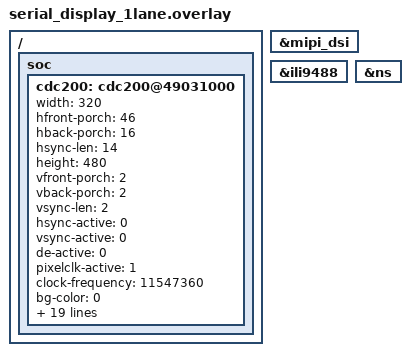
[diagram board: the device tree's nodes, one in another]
/* Copyright (C) 2024 Alif Semiconductor - All Rights Reserved.
 * Use, distribution and modification of this code is permitted under the
 * terms stated in the Alif Semiconductor Software License Agreement
 *
 * You should have received a copy of the Alif Semiconductor Software
 * License Agreement with this file. If not, please write to:
 * contact@alifsemi.com, or visit: https://alifsemi.com/license
 *
 */

/ {
	soc {
		cdc200: cdc200@49031000 {
			width = <320>;
			hfront-porch = <46>;
			hback-porch = <16>;
			hsync-len = <14>;

			height = <480>;
			vfront-porch = <2>;
			vback-porch = <2>;
			vsync-len = <2>;

			hsync-active = <0>;
			vsync-active = <0>;
			de-active = <0>;
			pixelclk-active = <1>;

			clock-frequency = <11547360>;

			bg-color = <0>;
			enable-l1 = <1>;
			pixel-fmt-l1 = "rgb-565";
			def-back-color-l1 = <0>;
			win-x0-l1 = <0>;
			win-y0-l1 = <0>;
			win-x1-l1 = <320>;
			win-y1-l1 = <480>;
			blend-factor1-l1 = <4>;
			blend-factor2-l1 = <5>;
			const-alpha-l1 = <0xff>;
			enable-l2 = <0>;
			pixel-fmt-l2 = "undefined";
			win-x0-l2 = <0>;
			win-y0-l2 = <0>;
			win-x1-l2 = <0>;
			win-y1-l2 = <0>;
			blend-factor1-l2 = <6>;
			blend-factor2-l2 = <7>;
			const-alpha-l2 = <0xff>;
		};
	};
};

&mipi_dsi {
	//dpi-video-pattern-gen = "vertical-color-bar";
	//dpi-video-pattern-gen = "horizontal-color-bar";
	//dpi-video-pattern-gen = "vertical-bit-error-rate";
	status = "okay";
};

&ili9488 {
	status = "okay";
};

ns: &ns {
	status = "okay";
};
